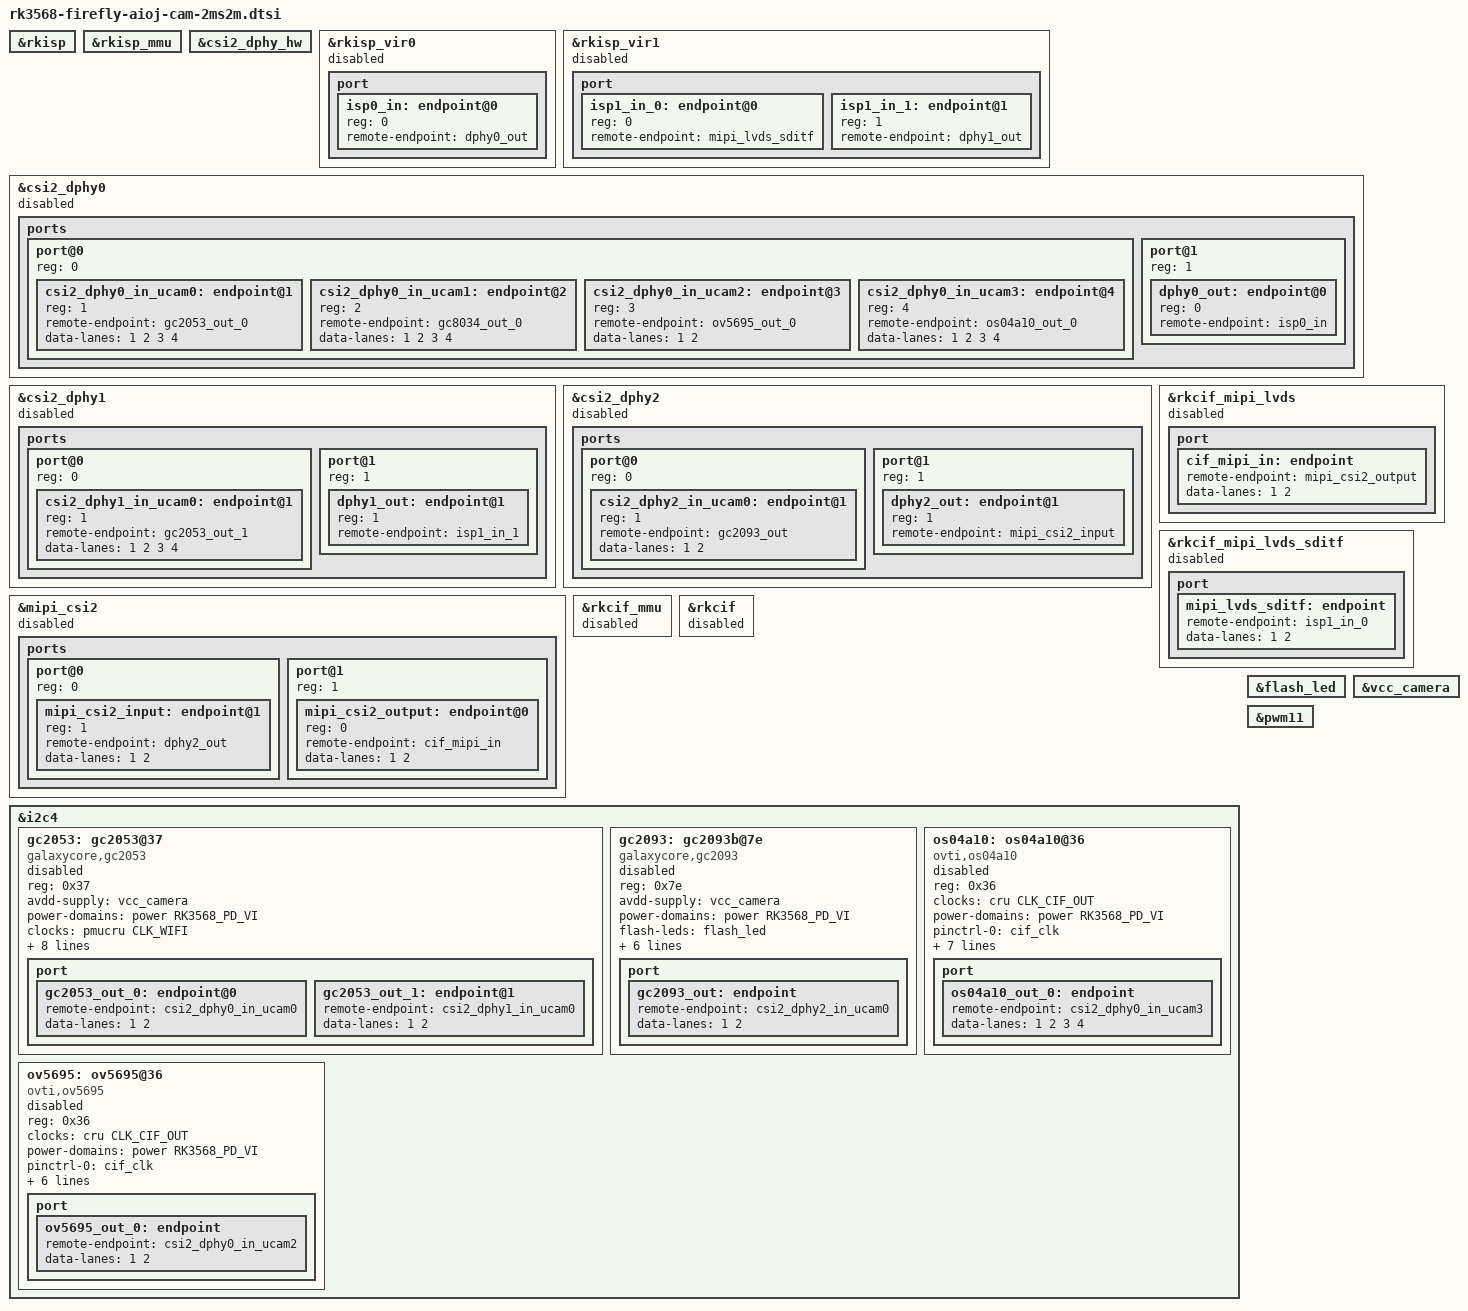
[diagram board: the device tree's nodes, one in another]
// SPDX-License-Identifier: (GPL-2.0+ OR MIT)
/*
 * Copyright (c) 2020 Rockchip Electronics Co., Ltd.
 *
 */

&rkisp {
	status = "okay";
};

&rkisp_mmu {
	status = "okay";
};

&csi2_dphy_hw {
	status = "okay";
};

&rkisp_vir0 {
	status = "disabled";
	port {
		#address-cells = <1>;
		#size-cells = <0>;

		isp0_in: endpoint@0 {
			reg = <0>;
			remote-endpoint = <&dphy0_out>;
		};
	};
};

&rkisp_vir1 {
	status = "disabled";
	port {
		#address-cells = <1>;
		#size-cells = <0>;

		isp1_in_0: endpoint@0 {
			reg = <0>;
			remote-endpoint = <&mipi_lvds_sditf>;
		};
		isp1_in_1: endpoint@1 {
			reg = <1>;
			remote-endpoint = <&dphy1_out>;
		};
	};
};

&csi2_dphy_hw {
	status = "okay";
};

&csi2_dphy0 {
	status = "disabled";

	ports {
		#address-cells = <1>;
		#size-cells = <0>;

		port@0 {
			reg = <0>;
			#address-cells = <1>;
			#size-cells = <0>;

			csi2_dphy0_in_ucam0: endpoint@1 {
				reg = <1>;
				remote-endpoint = <&gc2053_out_0>;
				data-lanes = <1 2 3 4>;
			};

			csi2_dphy0_in_ucam1: endpoint@2 {
				reg = <2>;
				remote-endpoint = <&gc8034_out_0>;
				data-lanes = <1 2 3 4>;
			};

			csi2_dphy0_in_ucam2: endpoint@3 {
				reg = <3>;
				remote-endpoint = <&ov5695_out_0>;
				data-lanes = <1 2>;
			};

			csi2_dphy0_in_ucam3: endpoint@4 {
				reg = <4>;
				remote-endpoint = <&os04a10_out_0>;
				data-lanes = <1 2 3 4>;
			};
		};

		port@1 {
			reg = <1>;
			#address-cells = <1>;
			#size-cells = <0>;

			dphy0_out: endpoint@0 {
				reg = <0>;
				remote-endpoint = <&isp0_in>;
			};
		};
	};
};

&csi2_dphy1 {
	status = "disabled";
	/*
	 * dphy1 only used for split mode,
	 * can be used concurrently with dphy2
	 * full mode and split mode are mutually exclusive
	 */
	ports {
		#address-cells = <1>;
		#size-cells = <0>;

		port@0 {
			reg = <0>;
			#address-cells = <1>;
			#size-cells = <0>;

			csi2_dphy1_in_ucam0: endpoint@1 {
				reg = <1>;
				remote-endpoint = <&gc2053_out_1>;
				data-lanes = <1 2 3 4>;
			};
			/*
			csi2_dphy1_in_ucam1: endpoint@2 {
				reg = <2>;
				remote-endpoint = <&gc8034_out_1>;
				data-lanes = <1 2 3 4>;
			};

			csi2_dphy1_in_ucam2: endpoint@3 {
				reg = <3>;
				remote-endpoint = <&ov5695_out_1>;
				data-lanes = <1 2>;
			};

			csi2_dphy1_in_ucam3: endpoint@4 {
				reg = <4>;
				remote-endpoint = <&os04a10_out_1>;
				data-lanes = <1 2 3 4>;
			};
			*/
		};

		port@1 {
			reg = <1>;
			#address-cells = <1>;
			#size-cells = <0>;

			dphy1_out: endpoint@1 {
				reg = <1>;
				remote-endpoint = <&isp1_in_1>;
			};
		};
	};
};

&csi2_dphy2 {
	status = "disabled";
	/*
	 * dphy2 only used for split mode,
	 * can be used concurrently with dphy1
	 * full mode and split mode are mutually exclusive
	 */
	ports {
		#address-cells = <1>;
		#size-cells = <0>;

		port@0 {
			reg = <0>;
			#address-cells = <1>;
			#size-cells = <0>;

			csi2_dphy2_in_ucam0: endpoint@1 {
				reg = <1>;
				remote-endpoint = <&gc2093_out>;
				data-lanes = <1 2>;
			};
		};

		port@1 {
			reg = <1>;
			#address-cells = <1>;
			#size-cells = <0>;

			dphy2_out: endpoint@1 {
				reg = <1>;
				remote-endpoint = <&mipi_csi2_input>;
			};
		};
	};
};

&mipi_csi2 {
    status = "disabled";

    ports {
        #address-cells = <1>;
        #size-cells = <0>;

        port@0 {
            reg = <0>;
            #address-cells = <1>;
            #size-cells = <0>;

            mipi_csi2_input: endpoint@1 {
                    reg = <1>;
                    remote-endpoint = <&dphy2_out>;
                    data-lanes = <1 2>;
            };
        };

        port@1 {
            reg = <1>;
            #address-cells = <1>;
            #size-cells = <0>;

            mipi_csi2_output: endpoint@0 {
                    reg = <0>;
                    remote-endpoint = <&cif_mipi_in>;
                    data-lanes = <1 2>;
            };
        };
    };
};

&rkcif_mipi_lvds {
    status = "disabled";
    port {
        cif_mipi_in: endpoint {
            remote-endpoint = <&mipi_csi2_output>;
            data-lanes = <1 2>;
        };
    };
};

&rkcif_mipi_lvds_sditf {
    status = "disabled";
    port {
        mipi_lvds_sditf: endpoint {
            remote-endpoint = <&isp1_in_0>;
            data-lanes = <1 2>;
        };
    };
};


&rkcif_mmu {
    status = "disabled";
};

&rkcif {
    status = "disabled";
};

&i2c4 {
	status = "okay";
	gc2053: gc2053@37 { //IR
		status = "disabled";
		compatible = "galaxycore,gc2053";
		reg = <0x37>;

		avdd-supply = <&vcc_camera>;
		power-domains = <&power RK3568_PD_VI>;
		clocks = <&pmucru CLK_WIFI>;
		clock-names = "xvclk";
		pinctrl-names = "default";
		pinctrl-0 = <&refclk_pins>;

		//power-gpios = <&pca9555 PCA_IO0_3 GPIO_ACTIVE_HIGH>; //IR_PWR_EN
		power-gpios = <&pca9555 PCA_IO0_0 GPIO_ACTIVE_HIGH>; //IR_PWR_EN
		pwdn-gpios = <&pca9555 PCA_IO0_4 GPIO_ACTIVE_LOW>;

		firefly,clkout-enabled-index = <1>;
		rockchip,camera-module-index = <0>;
		rockchip,camera-module-facing = "back";
		rockchip,camera-module-name = "YT-RV1109-2-V1";
		rockchip,camera-module-lens-name = "40IR-2MP-F20";
		port {
			gc2053_out_0: endpoint@0 {
				remote-endpoint = <&csi2_dphy0_in_ucam0>;
				data-lanes = <1 2>;
			};
			gc2053_out_1: endpoint@1 {
				remote-endpoint = <&csi2_dphy1_in_ucam0>;
				data-lanes = <1 2>;
			};
		};
	};

	gc2093: gc2093b@7e { //RGB
		status = "disabled";
		compatible = "galaxycore,gc2093";
		reg = <0x7e>;

		avdd-supply = <&vcc_camera>;
		power-domains = <&power RK3568_PD_VI>;
		//clocks = <&pmucru CLK_WIFI>;
		clock-names = "xvclk";
		pinctrl-names = "default";
		//pinctrl-0 = <&refclk_pins>;
		flash-leds = <&flash_led>;

		pwdn-gpios = <&pca9555 PCA_IO0_1 GPIO_ACTIVE_HIGH>;

		firefly,clkout-enabled-index = <0>;
		rockchip,camera-module-index = <1>;
		rockchip,camera-module-facing = "front";
		rockchip,camera-module-name = "YT-RV1109-2-V1";
		rockchip,camera-module-lens-name = "40IR-2MP-F20";
		port {
			gc2093_out: endpoint {
				remote-endpoint = <&csi2_dphy2_in_ucam0>;
				data-lanes = <1 2>;
			};
		};
	};

	os04a10: os04a10@36 {
		status = "disabled";
		compatible = "ovti,os04a10";
		reg = <0x36>;
		clocks = <&cru CLK_CIF_OUT>;
		clock-names = "xvclk";
		power-domains = <&power RK3568_PD_VI>;
		pinctrl-names = "default";
		pinctrl-0 = <&cif_clk>;
		reset-gpios = <&gpio3 RK_PB6 GPIO_ACTIVE_LOW>;
		pwdn-gpios = <&gpio4 RK_PB4 GPIO_ACTIVE_HIGH>;
		rockchip,camera-module-index = <0>;
		rockchip,camera-module-facing = "back";
		rockchip,camera-module-name = "CMK-OT1607-FV1";
		rockchip,camera-module-lens-name = "M12-40IRC-4MP-F16";
		port {
			os04a10_out_0: endpoint {
				remote-endpoint = <&csi2_dphy0_in_ucam3>;
				data-lanes = <1 2 3 4>;
			};
		};
	};

	ov5695: ov5695@36 {
		status = "disabled";
		compatible = "ovti,ov5695";
		reg = <0x36>;
		clocks = <&cru CLK_CIF_OUT>;
		clock-names = "xvclk";
		power-domains = <&power RK3568_PD_VI>;
		pinctrl-names = "default";
		pinctrl-0 = <&cif_clk>;
		reset-gpios = <&gpio3 RK_PB6 GPIO_ACTIVE_HIGH>;
		pwdn-gpios = <&gpio4 RK_PB4 GPIO_ACTIVE_HIGH>;
		rockchip,camera-module-index = <0>;
		rockchip,camera-module-facing = "back";
		rockchip,camera-module-name = "TongJu";
		rockchip,camera-module-lens-name = "CHT842-MD";
		port {
			ov5695_out_0: endpoint {
				remote-endpoint = <&csi2_dphy0_in_ucam2>;
				data-lanes = <1 2>;
			};
		};
	};
};

&flash_led {
	status = "okay";
};

&vcc_camera {
	status = "okay";
};

&pwm11 {
	status = "okay";
};
